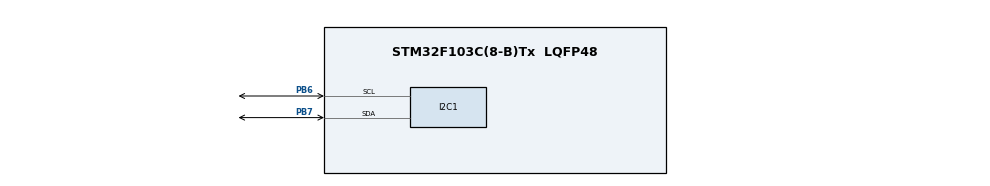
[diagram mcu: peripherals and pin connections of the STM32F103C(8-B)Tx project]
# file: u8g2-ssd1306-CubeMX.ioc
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Dma.I2C1_RX.1.Direction=DMA_PERIPH_TO_MEMORY
Dma.I2C1_RX.1.Instance=DMA1_Channel7
Dma.I2C1_RX.1.MemDataAlignment=DMA_MDATAALIGN_BYTE
Dma.I2C1_RX.1.MemInc=DMA_MINC_ENABLE
Dma.I2C1_RX.1.Mode=DMA_NORMAL
Dma.I2C1_RX.1.PeriphDataAlignment=DMA_PDATAALIGN_BYTE
Dma.I2C1_RX.1.PeriphInc=DMA_PINC_DISABLE
Dma.I2C1_RX.1.Priority=DMA_PRIORITY_LOW
Dma.I2C1_TX.0.Direction=DMA_MEMORY_TO_PERIPH
Dma.I2C1_TX.0.Instance=DMA1_Channel6
Dma.I2C1_TX.0.MemDataAlignment=DMA_MDATAALIGN_BYTE
Dma.I2C1_TX.0.MemInc=DMA_MINC_ENABLE
Dma.I2C1_TX.0.Mode=DMA_NORMAL
Dma.I2C1_TX.0.PeriphDataAlignment=DMA_PDATAALIGN_BYTE
Dma.I2C1_TX.0.PeriphInc=DMA_PINC_DISABLE
Dma.I2C1_TX.0.Priority=DMA_PRIORITY_LOW
Dma.Request0=I2C1_TX
Dma.Request1=I2C1_RX
I2C1.I2C_Mode=I2C_Standard
Mcu.Family=STM32F1
Mcu.Name=STM32F103C(8-B)Tx
Mcu.Package=LQFP48
NVIC.DMA1_Channel6_IRQn=true\:0\:0\:false\:false\:true\:false
NVIC.DMA1_Channel7_IRQn=true\:0\:0\:false\:false\:true\:false
NVIC.I2C1_ER_IRQn=true\:0\:0\:false\:false\:true\:true
NVIC.I2C1_EV_IRQn=true\:0\:0\:false\:false\:true\:true
NVIC.PriorityGroup=NVIC_PRIORITYGROUP_4
PA13.Mode=Serial_Wire
PA13.Signal=SYS_JTMS-SWDIO
PA14.Mode=Serial_Wire
PA14.Signal=SYS_JTCK-SWCLK
PB6.Mode=I2C
PB6.Signal=I2C1_SCL
PB7.Mode=I2C
PB7.Signal=I2C1_SDA
ProjectManager.HeapSize=0x200
ProjectManager.StackSize=0x400
ProjectManager.TargetToolchain=TrueSTUDIO
RCC.APB1Freq_Value=8000000
RCC.APB2Freq_Value=8000000
board=custom

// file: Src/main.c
/**
  ******************************************************************************
  * @file           : main.c
  * @brief          : Main program body
  ******************************************************************************
  ** This notice applies to any and all portions of this file
  * that are not between comment pairs USER CODE BEGIN and
  * USER CODE END. Other portions of this file, whether
  * inserted by the user or by software development tools
  * are owned by their respective copyright owners.
  *
  * COPYRIGHT(c) 2018 STMicroelectronics
  *
  * Redistribution and use in source and binary forms, with or without modification,
  * are permitted provided that the following conditions are met:
  *   1. Redistributions of source code must retain the above copyright notice,
  *      this list of conditions and the following disclaimer.
  *   2. Redistributions in binary form must reproduce the above copyright notice,
  *      this list of conditions and the following disclaimer in the documentation
  *      and/or other materials provided with the distribution.
  *   3. Neither the name of STMicroelectronics nor the names of its contributors
  *      may be used to endorse or promote products derived from this software
  *      without specific prior written permission.
  *
  * THIS SOFTWARE IS PROVIDED BY THE COPYRIGHT HOLDERS AND CONTRIBUTORS "AS IS"
  * AND ANY EXPRESS OR IMPLIED WARRANTIES, INCLUDING, BUT NOT LIMITED TO, THE
  * IMPLIED WARRANTIES OF MERCHANTABILITY AND FITNESS FOR A PARTICULAR PURPOSE ARE
  * DISCLAIMED. IN NO EVENT SHALL THE COPYRIGHT HOLDER OR CONTRIBUTORS BE LIABLE
  * FOR ANY DIRECT, INDIRECT, INCIDENTAL, SPECIAL, EXEMPLARY, OR CONSEQUENTIAL
  * DAMAGES (INCLUDING, BUT NOT LIMITED TO, PROCUREMENT OF SUBSTITUTE GOODS OR
  * SERVICES; LOSS OF USE, DATA, OR PROFITS; OR BUSINESS INTERRUPTION) HOWEVER
  * CAUSED AND ON ANY THEORY OF LIABILITY, WHETHER IN CONTRACT, STRICT LIABILITY,
  * OR TORT (INCLUDING NEGLIGENCE OR OTHERWISE) ARISING IN ANY WAY OUT OF THE USE
  * OF THIS SOFTWARE, EVEN IF ADVISED OF THE POSSIBILITY OF SUCH DAMAGE.
  *
  ******************************************************************************
  */
#include "main.h"
#include "stm32f1xx_hal.h"

/* USER CODE BEGIN Includes */
#include "u8g2.h"
/* USER CODE END Includes */

I2C_HandleTypeDef hi2c1;
DMA_HandleTypeDef hdma_i2c1_tx;
DMA_HandleTypeDef hdma_i2c1_rx;

/* USER CODE BEGIN PV */

u8x8_t u8x8;                    // u8x8 object
u8g2_t u8g2;
/* Private variables ---------------------------------------------------------*/
#define I2C_ADDRESS 0x3C
/* USER CODE END PV */

void SystemClock_Config(void);
static void MX_GPIO_Init(void);
static void MX_DMA_Init(void);
static void MX_I2C1_Init(void);

/* USER CODE BEGIN PFP */
/* Private function prototypes -----------------------------------------------*/

/* USER CODE END PFP */

/* USER CODE BEGIN 0 */

uint8_t u8x8_byte_stm32hal_hw_i2c(u8x8_t *u8x8, uint8_t msg, uint8_t arg_int, void *arg_ptr)
{
	static uint8_t buffer[32];		/* u8g2/u8x8 will never send more than 32 bytes between START_TRANSFER and END_TRANSFER */
	static uint8_t buf_idx;
	uint8_t *data;

  switch(msg)
  {
    case U8X8_MSG_BYTE_SEND:
    {
        data = (uint8_t *)arg_ptr;
        while( arg_int > 0 )
        {
			buffer[buf_idx++] = *data;
			data++;
			arg_int--;
        }
    }
    	break;
    case U8X8_MSG_BYTE_INIT:
    	break;
    case U8X8_MSG_BYTE_SET_DC:
    	break;
    case U8X8_MSG_BYTE_START_TRANSFER:
		{
			buf_idx = 0;
		}
		break;
    case U8X8_MSG_BYTE_END_TRANSFER:
	{
		uint8_t iaddress = I2C_ADDRESS;
		HAL_I2C_Master_Transmit_DMA(&hi2c1, (uint16_t)iaddress<<1, &buffer[0], buf_idx);
		//HAL_I2C_Master_Transmit(&hi2c1, (uint16_t)iaddress<<1, &buffer[0], buf_idx, 20u);
		//TODO Investigate why delay is needed here.
		//Seems like DMA feeding bytes too fast.
		volatile uint32_t i;
		for (i = 1; i <= 500; i++);
	}
    	break;
    default:
      return 0;
  }
  return 1;
}

uint8_t psoc_gpio_and_delay_cb(u8x8_t *u8x8, uint8_t msg, uint8_t arg_int, void *arg_ptr)
{
  switch(msg)
  {
    case U8X8_MSG_GPIO_AND_DELAY_INIT:
      /* only support for software I2C*/

      break;
    case U8X8_MSG_DELAY_NANO:
      /* not required for SW I2C */
    {
		volatile uint32_t i;
		for (i = 1; i <= arg_int*10; i++);
    }
      break;

    case U8X8_MSG_DELAY_10MICRO:
      /* not used at the moment */
      break;

    case U8X8_MSG_DELAY_100NANO:
      /* not used at the moment */
      break;

    case U8X8_MSG_DELAY_MILLI:
      HAL_Delay(arg_int);
      break;
    case U8X8_MSG_DELAY_I2C:
      /* arg_int is 1 or 4: 100KHz (5us) or 400KHz (1.25us) */
      //delay_micro_seconds(arg_int<=2?5:1);
      break;

    case U8X8_MSG_GPIO_I2C_CLOCK:

      break;
/*
    case U8X8_MSG_GPIO_MENU_SELECT:
      u8x8_SetGPIOResult(u8x8, Chip_GPIO_GetPinState(LPC_GPIO, KEY_SELECT_PORT, KEY_SELECT_PIN));
      break;
    case U8X8_MSG_GPIO_MENU_NEXT:
      u8x8_SetGPIOResult(u8x8, Chip_GPIO_GetPinState(LPC_GPIO, KEY_NEXT_PORT, KEY_NEXT_PIN));
      break;
    case U8X8_MSG_GPIO_MENU_PREV:
      u8x8_SetGPIOResult(u8x8, Chip_GPIO_GetPinState(LPC_GPIO, KEY_PREV_PORT, KEY_PREV_PIN));
      break;

    case U8X8_MSG_GPIO_MENU_HOME:
      u8x8_SetGPIOResult(u8x8, Chip_GPIO_GetPinState(LPC_GPIO, KEY_HOME_PORT, KEY_HOME_PIN));
      break;
*/
    default:
      u8x8_SetGPIOResult(u8x8, 1);
      break;
  }
  return 1;
}
/* USER CODE END 0 */

int main(void)
{

  /* MCU Configuration----------------------------------------------------------*/

  /* Reset of all peripherals, Initializes the Flash interface and the Systick. */
  HAL_Init();

  /* Configure the system clock */
  SystemClock_Config();

  /* Initialize all configured peripherals */
  MX_GPIO_Init();
  MX_DMA_Init();
  MX_I2C1_Init();
  /* USER CODE BEGIN 2 */
#ifdef USE_U8X8
  u8x8_Setup(&u8x8,
		  u8x8_d_ssd1306_128x64_noname,
		  u8x8_cad_ssd13xx_i2c,
		  u8x8_byte_stm32hal_hw_i2c,
		  psoc_gpio_and_delay_cb);

  u8x8_InitDisplay(&u8x8);
  u8x8_SetPowerSave(&u8x8, 0);
  u8x8_ClearDisplay(&u8x8);
  u8x8_SetFont(&u8x8, u8x8_font_amstrad_cpc_extended_r);
#else
  u8g2_Setup_ssd1306_i2c_128x64_noname_f(&u8g2,
		  U8G2_R0,
		  u8x8_byte_stm32hal_hw_i2c,
		  psoc_gpio_and_delay_cb);
  u8g2_SetI2CAddress(&u8g2, I2C_ADDRESS*2);
  u8g2_InitDisplay(&u8g2);
  u8g2_SetPowerSave(&u8g2, 0);
  u8g2_ClearDisplay(&u8g2);

  u8g2_SetDrawColor(&u8g2, 1);
  u8g2_SetFontDirection(&u8g2, 0);
#endif
  /* USER CODE END 2 */

  /* Infinite loop */
  while (1)
  {

  /* USER CODE BEGIN 3 */
#ifdef USE_U8X8
	  u8x8_ClearDisplay(&u8x8);
      u8x8_DrawString(&u8x8, 0, 0, "Hello World!");
      HAL_Delay(500u);
#else
		u8g2_ClearBuffer(&u8g2);

		u8g2_SetFontMode(&u8g2, 1);	// Transparent
		u8g2_SetFontDirection(&u8g2, 0);
		u8g2_SetFont(&u8g2, u8g2_font_inb24_mf);
		u8g2_DrawStr(&u8g2, 0, 30, "U");

		u8g2_SetFontDirection(&u8g2, 1);
		u8g2_SetFont(&u8g2, u8g2_font_inb30_mn);
		u8g2_DrawStr(&u8g2, 21,8,"8");

		u8g2_SetFontDirection(&u8g2, 0);
		u8g2_SetFont(&u8g2, u8g2_font_inb24_mf);
		u8g2_DrawStr(&u8g2, 51,30,"g");
		u8g2_DrawStr(&u8g2, 67,30,"\xb2");

		u8g2_DrawHLine(&u8g2, 2, 35, 47);
		u8g2_DrawHLine(&u8g2, 3, 36, 47);
		u8g2_DrawVLine(&u8g2, 45, 32, 12);
		u8g2_DrawVLine(&u8g2, 46, 33, 12);

		u8g2_SetFont(&u8g2, u8g2_font_4x6_tr);

		u8g2_DrawStr(&u8g2, 1,54,"github.com/olikraus/u8g2");

		u8g2_SendBuffer(&u8g2);
#endif
      HAL_Delay(2000);
  }
  /* USER CODE END 3 */

}

void SystemClock_Config(void)
{

  RCC_OscInitTypeDef RCC_OscInitStruct;
  RCC_ClkInitTypeDef RCC_ClkInitStruct;

    /**Initializes the CPU, AHB and APB busses clocks
    */
  RCC_OscInitStruct.OscillatorType = RCC_OSCILLATORTYPE_HSI;
  RCC_OscInitStruct.HSIState = RCC_HSI_ON;
  RCC_OscInitStruct.HSICalibrationValue = 16;
  RCC_OscInitStruct.PLL.PLLState = RCC_PLL_NONE;
  if (HAL_RCC_OscConfig(&RCC_OscInitStruct) != HAL_OK)
  {
    _Error_Handler(__FILE__, __LINE__);
  }

    /**Initializes the CPU, AHB and APB busses clocks
    */
  RCC_ClkInitStruct.ClockType = RCC_CLOCKTYPE_HCLK|RCC_CLOCKTYPE_SYSCLK
                              |RCC_CLOCKTYPE_PCLK1|RCC_CLOCKTYPE_PCLK2;
  RCC_ClkInitStruct.SYSCLKSource = RCC_SYSCLKSOURCE_HSI;
  RCC_ClkInitStruct.AHBCLKDivider = RCC_SYSCLK_DIV1;
  RCC_ClkInitStruct.APB1CLKDivider = RCC_HCLK_DIV1;
  RCC_ClkInitStruct.APB2CLKDivider = RCC_HCLK_DIV1;

  if (HAL_RCC_ClockConfig(&RCC_ClkInitStruct, FLASH_LATENCY_0) != HAL_OK)
  {
    _Error_Handler(__FILE__, __LINE__);
  }

    /**Configure the Systick interrupt time
    */
  HAL_SYSTICK_Config(HAL_RCC_GetHCLKFreq()/1000);

    /**Configure the Systick
    */
  HAL_SYSTICK_CLKSourceConfig(SYSTICK_CLKSOURCE_HCLK);

  /* SysTick_IRQn interrupt configuration */
  HAL_NVIC_SetPriority(SysTick_IRQn, 0, 0);
}

/* I2C1 init function */
static void MX_I2C1_Init(void)
{

  hi2c1.Instance = I2C1;
  hi2c1.Init.ClockSpeed = 400000;
  hi2c1.Init.DutyCycle = I2C_DUTYCYCLE_2;
  hi2c1.Init.OwnAddress1 = 0;
  hi2c1.Init.AddressingMode = I2C_ADDRESSINGMODE_7BIT;
  hi2c1.Init.DualAddressMode = I2C_DUALADDRESS_DISABLE;
  hi2c1.Init.OwnAddress2 = 0;
  hi2c1.Init.GeneralCallMode = I2C_GENERALCALL_DISABLE;
  hi2c1.Init.NoStretchMode = I2C_NOSTRETCH_DISABLE;
  if (HAL_I2C_Init(&hi2c1) != HAL_OK)
  {
    _Error_Handler(__FILE__, __LINE__);
  }

}

static void MX_DMA_Init(void)
{
  /* DMA controller clock enable */
  __HAL_RCC_DMA1_CLK_ENABLE();

  /* DMA interrupt init */
  /* DMA1_Channel6_IRQn interrupt configuration */
  HAL_NVIC_SetPriority(DMA1_Channel6_IRQn, 0, 0);
  HAL_NVIC_EnableIRQ(DMA1_Channel6_IRQn);
  /* DMA1_Channel7_IRQn interrupt configuration */
  HAL_NVIC_SetPriority(DMA1_Channel7_IRQn, 0, 0);
  HAL_NVIC_EnableIRQ(DMA1_Channel7_IRQn);

}

/** Configure pins as
        * Analog
        * Input
        * Output
        * EVENT_OUT
        * EXTI
*/
static void MX_GPIO_Init(void)
{

  /* GPIO Ports Clock Enable */
  __HAL_RCC_GPIOA_CLK_ENABLE();
  __HAL_RCC_GPIOB_CLK_ENABLE();

}

/* USER CODE BEGIN 4 */
void HAL_I2C_ErrorCallback(I2C_HandleTypeDef *hi2c)
{
	  while(1)
	  {
	  }
}
/* USER CODE END 4 */

void _Error_Handler(char *file, int line)
{
  while(1)
  {
  }
}

/************************ (C) COPYRIGHT STMicroelectronics *****END OF FILE****/
